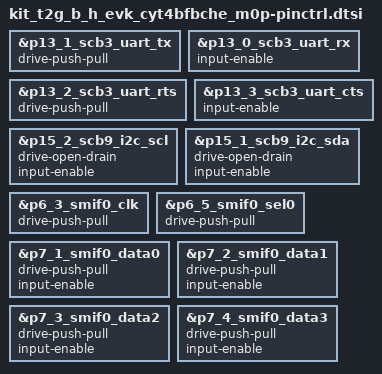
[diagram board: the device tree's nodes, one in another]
/*
 * Copyright (c) 2025 Infineon Technologies AG,
 * or an affiliate of Infineon Technologies AG.
 *
 * SPDX-License-Identifier: Apache-2.0
 */

/* Configure pin control bias mode for uart pins */
&p13_1_scb3_uart_tx {
	drive-push-pull;
};

&p13_0_scb3_uart_rx {
	input-enable;
};

&p13_2_scb3_uart_rts {
	drive-push-pull;
};

&p13_3_scb3_uart_cts {
	input-enable;
};

&p15_2_scb9_i2c_scl {
    drive-open-drain;
    input-enable;
};

&p15_1_scb9_i2c_sda {
    drive-open-drain;
    input-enable;
};

/* SMIF0 / QSPI NOR flash pin drive modes */
&p6_3_smif0_clk {
    drive-push-pull;
};

&p6_5_smif0_sel0 {
    drive-push-pull;
};

&p7_1_smif0_data0 {
    drive-push-pull;
    input-enable;
};

&p7_2_smif0_data1 {
    drive-push-pull;
    input-enable;
};

&p7_3_smif0_data2 {
    drive-push-pull;
    input-enable;
};

&p7_4_smif0_data3 {
    drive-push-pull;
    input-enable;
};
